AUTOSAR XML (schema 3.1.2)
package /Components/SWC_MPM
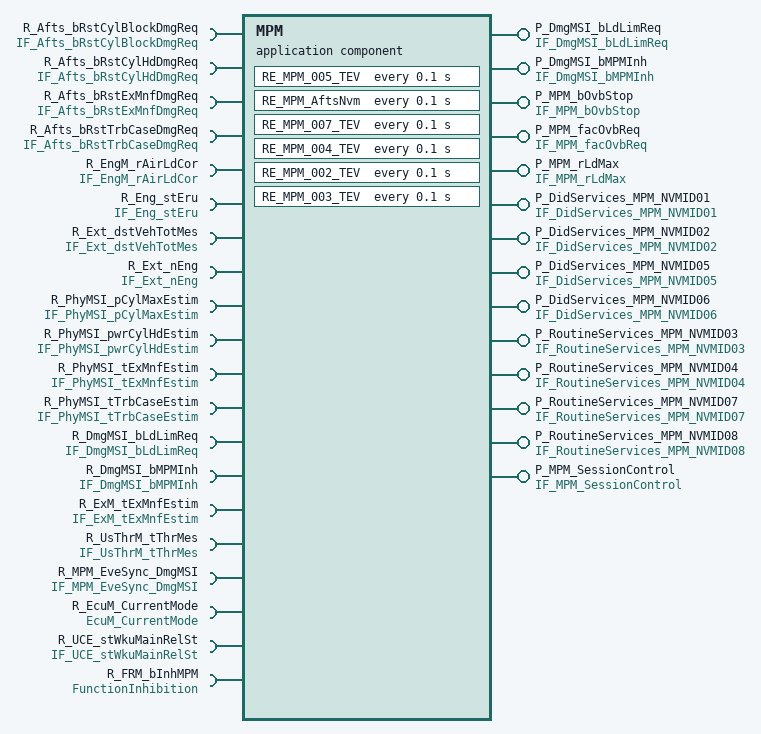
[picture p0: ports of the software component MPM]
  application software component type MPM
    20 x require port:
      R_Afts_bRstCylBlockDmgReq: unqueued-receiver-com-spec{data-element=Afts_bRstCylBlockDmgReq, init-value=ConstantValue, resync-time=0}, required-interface=IF_Afts_bRstCylBlockDmgReq  # Receiver of interface IF_Afts_bRstCylBlockDmgReq - Requirement Reference: [01552_11_02147-MPM-I003(0)]
      R_Afts_bRstCylHdDmgReq: unqueued-receiver-com-spec{data-element=Afts_bRstCylHdDmgReq, init-value=ConstantValue1, resync-time=0}, required-interface=IF_Afts_bRstCylHdDmgReq  # Receiver of interface IF_Afts_bRstCylHdDmgReq - Requirement Reference: [01552_11_02147-MPM-I004(0)]
      R_Afts_bRstExMnfDmgReq: unqueued-receiver-com-spec{data-element=Afts_bRstExMnfDmgReq, init-value=ConstantValue3, resync-time=0}, required-interface=IF_Afts_bRstExMnfDmgReq  # Receiver of interface IF_Afts_bRstExMnfDmgReq - Requirement Reference: [01552_11_02147-MPM-I005(0)]
      R_Afts_bRstTrbCaseDmgReq: unqueued-receiver-com-spec{data-element=Afts_bRstTrbCaseDmgReq, init-value=ConstantValue5, resync-time=0}, required-interface=IF_Afts_bRstTrbCaseDmgReq  # Receiver of interface IF_Afts_bRstTrbCaseDmgReq - Requirement Reference: [01552_11_02147-MPM-I006(0)]
      R_EngM_rAirLdCor: unqueued-receiver-com-spec{data-element=EngM_rAirLdCor, init-value=ConstantValue7, resync-time=0}, required-interface=IF_EngM_rAirLdCor  # Receiver of interface IF_EngM_rAirLdCor - Requirement Reference: [01552_11_02147-MPM-I007(0)]
      R_Eng_stEru: unqueued-receiver-com-spec{data-element=Eng_stEru, init-value=ConstantValue9, resync-time=0}, required-interface=IF_Eng_stEru  # Receiver of interface IF_Eng_stEru - Requirement Reference: [01552_11_02147-MPM-I008(0)]
      R_Ext_dstVehTotMes: unqueued-receiver-com-spec{data-element=Ext_dstVehTotMes, init-value=ConstantValue11, resync-time=0}, required-interface=IF_Ext_dstVehTotMes  # Receiver of interface IF_Ext_dstVehTotMes - Requirement Reference: [01552_11_02147-MPM-I009(0)]
      R_Ext_nEng: unqueued-receiver-com-spec{data-element=Ext_nEng, init-value=ConstantValue13, resync-time=0}, required-interface=IF_Ext_nEng  # Receiver of interface IF_Ext_nEng - Requirement Reference: [01552_11_02147-MPM-I010(0)]
      R_PhyMSI_pCylMaxEstim: unqueued-receiver-com-spec{data-element=PhyMSI_pCylMaxEstim, init-value=ConstantValue15, resync-time=0}, required-interface=IF_PhyMSI_pCylMaxEstim  # Receiver of interface IF_PhyMSI_pCylMaxEstim - Requirement Reference: [01552_11_02147-MPM-I011(0)]
      R_PhyMSI_pwrCylHdEstim: unqueued-receiver-com-spec{data-element=PhyMSI_pwrCylHdEstim, init-value=ConstantValue17, resync-time=0}, required-interface=IF_PhyMSI_pwrCylHdEstim  # Receiver of interface IF_PhyMSI_pwrCylHdEstim - Requirement Reference: [01552_11_02147-MPM-I012(0)]
      R_PhyMSI_tExMnfEstim: unqueued-receiver-com-spec{data-element=PhyMSI_tExMnfEstim, init-value=ConstantValue19, resync-time=0}, required-interface=IF_PhyMSI_tExMnfEstim  # Receiver of interface IF_PhyMSI_tExMnfEstim - Requirement Reference: [01552_11_02147-MPM-I013(0)]
      R_PhyMSI_tTrbCaseEstim: unqueued-receiver-com-spec{data-element=PhyMSI_tTrbCaseEstim, init-value=ConstantValue21, resync-time=0}, required-interface=IF_PhyMSI_tTrbCaseEstim  # Receiver of interface IF_PhyMSI_tTrbCaseEstim - Requirement Reference: [01552_11_02147-MPM-I014(0)]
      R_DmgMSI_bLdLimReq: unqueued-receiver-com-spec{data-element=DmgMSI_bLdLimReq, init-value=ConstantValue23, resync-time=0}, required-interface=IF_DmgMSI_bLdLimReq  # Receiver of interface IF_DmgMSI_bLdLimReq - Requirement Reference: [01552_11_02147-MPM-I018(0)]
      R_DmgMSI_bMPMInh: unqueued-receiver-com-spec{data-element=DmgMSI_bMPMInh, init-value=ConstantValue25, resync-time=0}, required-interface=IF_DmgMSI_bMPMInh  # Receiver of interface IF_DmgMSI_bMPMInh - Requirement Reference: [01552_11_02147-MPM-I019(0)]
      R_ExM_tExMnfEstim: unqueued-receiver-com-spec{data-element=ExM_tExMnfEstim, init-value=ConstantValue27, resync-time=0}, required-interface=IF_ExM_tExMnfEstim  # Receiver of interface IF_ExM_tExMnfEstim - Requirement Reference: [01552_11_02147-MPM-I020(0)]
      R_UsThrM_tThrMes: unqueued-receiver-com-spec{data-element=UsThrM_tThrMes, init-value=ConstantValue29, resync-time=0}, required-interface=IF_UsThrM_tThrMes  # Receiver of interface IF_UsThrM_tThrMes - Requirement Reference: [01552_11_02147-MPM-I021(0)]
      R_MPM_EveSync_DmgMSI: unqueued-receiver-com-spec{data-element=MPM_EveSync_DmgMSI, init-value=ConstantValue31, resync-time=0}, required-interface=IF_MPM_EveSync_DmgMSI  # Receiver of interface IF_MPM_EveSync_DmgMSI - Requirement Reference: [01552_11_02147-MPM-I022(0)]
      R_EcuM_CurrentMode: required-interface=EcuM_CurrentMode
      R_UCE_stWkuMainRelSt: required-interface=IF_UCE_stWkuMainRelSt
      R_FRM_bInhMPM: required-interface=FunctionInhibition  # 01552_11_02147-MPM-I095(0)
    14 x provide port:
      P_DmgMSI_bLdLimReq: unqueued-sender-com-spec{data-element=DmgMSI_bLdLimReq, can-invalidate=false, init-value=DmgMSI_bLdLimReq_Cst}, provided-interface=IF_DmgMSI_bLdLimReq
      P_DmgMSI_bMPMInh: unqueued-sender-com-spec{data-element=DmgMSI_bMPMInh, can-invalidate=false, init-value=DmgMSI_bMPMInh_Cst}, provided-interface=IF_DmgMSI_bMPMInh
      P_MPM_bOvbStop: unqueued-sender-com-spec{data-element=MPM_bOvbStop, can-invalidate=false, init-value=ConstantValue33}, provided-interface=IF_MPM_bOvbStop
      P_MPM_facOvbReq: unqueued-sender-com-spec{data-element=MPM_facOvbReq, can-invalidate=false, init-value=ConstantValue35}, provided-interface=IF_MPM_facOvbReq
      P_MPM_rLdMax: unqueued-sender-com-spec{data-element=MPM_rLdMax, can-invalidate=false, init-value=ConstantValue37}, provided-interface=IF_MPM_rLdMax
      P_DidServices_MPM_NVMID01: provided-interface=IF_DidServices_MPM_NVMID01
        provided-com-specs:
          operation=ConditionCheckWrite, queue-length=1
          operation=WriteData, queue-length=1
          operation=ConditionCheckRead, queue-length=1
          operation=ReadDataLength, queue-length=1
          operation=ReadData, queue-length=1
      P_DidServices_MPM_NVMID02: provided-interface=IF_DidServices_MPM_NVMID02
        provided-com-specs:
          operation=ReadData, queue-length=1
          operation=ConditionCheckRead, queue-length=1
          operation=ConditionCheckWrite, queue-length=1
          operation=WriteData, queue-length=1
          operation=ReadDataLength, queue-length=1
      P_DidServices_MPM_NVMID05: provided-interface=IF_DidServices_MPM_NVMID05
        provided-com-specs:
          operation=ConditionCheckRead, queue-length=1
          operation=ReadData, queue-length=1
          operation=ConditionCheckWrite, queue-length=1
          operation=WriteData, queue-length=1
          operation=ReadDataLength, queue-length=1
      P_DidServices_MPM_NVMID06: provided-interface=IF_DidServices_MPM_NVMID06
        provided-com-specs:
          operation=ConditionCheckRead, queue-length=1
          operation=ConditionCheckWrite, queue-length=1
          operation=ReadData, queue-length=1
          operation=ReadDataLength, queue-length=1
          operation=WriteData, queue-length=1
      P_RoutineServices_MPM_NVMID03: provided-com-specs=[{operation=Start, queue-length=1}, {operation=RequestResults, queue-length=1}], provided-interface=IF_RoutineServices_MPM_NVMID03
      P_RoutineServices_MPM_NVMID04: provided-com-specs=[{operation=Start, queue-length=1}, {operation=RequestResults, queue-length=1}], provided-interface=IF_RoutineServices_MPM_NVMID04
      P_RoutineServices_MPM_NVMID07: provided-com-specs=[{operation=RequestResults, queue-length=1}, {operation=Start, queue-length=1}], provided-interface=IF_RoutineServices_MPM_NVMID07
      P_RoutineServices_MPM_NVMID08: provided-com-specs=[{operation=RequestResults, queue-length=1}, {operation=Start, queue-length=1}], provided-interface=IF_RoutineServices_MPM_NVMID08
      P_MPM_SessionControl: provided-com-specs=[{operation=GetSesChgPermission, queue-length=1}, {operation=ChangeIndication, queue-length=1}], provided-interface=IF_MPM_SessionControl
  32 x constant specification:
    ConstantValue
      value:
        boolean literal ConstantValue: type=DT_Afts_bRstCylBlockDmgReq, value=false
    ConstantValue1
      value:
        boolean literal ConstantValue1: type=DT_Afts_bRstCylHdDmgReq, value=false
    ConstantValue11
      value:
        integer literal ConstantValue11: type=DT_Ext_dstVehTotMes, value=0
    ConstantValue13
      value:
        integer literal ConstantValue13: type=DT_Ext_nEng, value=0
    ConstantValue15
      value:
        integer literal ConstantValue15: type=DT_PhyMSI_pCylMaxEstim, value=0
    ConstantValue17
      value:
        integer literal ConstantValue17: type=DT_PhyMSI_pwrCylHdEstim, value=0
    ConstantValue19
      value:
        integer literal ConstantValue19: type=DT_PhyMSI_tExMnfEstim, value=7136
    ConstantValue21
      value:
        integer literal ConstantValue21: type=DT_PhyMSI_tTrbCaseEstim, value=7136
    ConstantValue23
      value:
        boolean literal ConstantValue23: type=DT_DmgMSI_bLdLimReq, value=false
    ConstantValue25
      value:
        boolean literal ConstantValue25: type=DT_DmgMSI_bMPMInh, value=false
    ConstantValue27
      value:
        integer literal ConstantValue27: type=DT_ExM_tExMnfEstim, value=4800
    ConstantValue29
      value:
        integer literal ConstantValue29: type=DT_UsThrM_tThrMes, value=0
    ConstantValue3
      value:
        boolean literal ConstantValue3: type=DT_Afts_bRstExMnfDmgReq, value=false
    ConstantValue31
      value:
        boolean literal ConstantValue31: type=DT_MPM_EveSync_DmgMSI, value=false
    ConstantValue33
      value:
        boolean literal ConstantValue33: type=DT_MPM_bOvbStop, value=false
    ConstantValue35
      value:
        integer literal ConstantValue35: type=DT_MPM_facOvbReq, value=0
    ConstantValue37
      value:
        integer literal ConstantValue37: type=DT_MPM_rLdMax, value=0
    ConstantValue5
      value:
        boolean literal ConstantValue5: type=DT_Afts_bRstTrbCaseDmgReq, value=false
    ConstantValue7
      value:
        integer literal ConstantValue7: type=DT_EngM_rAirLdCor, value=0
    ConstantValue9
      value:
        integer literal ConstantValue9: type=DT_Eng_stEru, value=1
    DmgMSI_bLdLimReq_Cst
      value:
        boolean literal DmgMSI_bLdLimReq_Cst: type=DT_DmgMSI_bLdLimReq, value=false
    DmgMSI_bMPMInh_Cst
      value:
        boolean literal DmgMSI_bMPMInh_Cst: type=DT_DmgMSI_bMPMInh, value=false
    DmgMSI_rCylBlockDmg_Cst
      value:
        integer literal DmgMSI_rCylBlockDmg_Cst: type=DT_DmgMSI_rCylBlockDmg, value=0
    DmgMSI_rCylHdDmg_Cst
      value:
        integer literal DmgMSI_rCylHdDmg_Cst: type=DT_DmgMSI_rCylHdDmg, value=0
    DmgMSI_rCylHdInjDmgCnt_Cst
      value:
        integer literal DmgMSI_rCylHdInjDmgCnt_Cst: type=DT_DmgMSI_rCylHdInjDmgCnt, value=0
    DmgMSI_rExMnfDmg_Cst
      value:
        integer literal DmgMSI_rExMnfDmg_Cst: type=DT_DmgMSI_rExMnfDmg, value=0
    DmgMSI_rTrbCaseDmg_Cst
      value:
        integer literal DmgMSI_rTrbCaseDmg_Cst: type=DT_DmgMSI_rTrbCaseDmg, value=0
    MPM_ctLockRqAftsNvm_Cst
      value:
        integer literal MPM_ctLockRqAftsNvm_Cst: type=DT_MPM_ctLockRqAftsNvm, value=0
    MPM_IDAftsNvm_Cst
      value:
        integer literal MPM_IDAftsNvm_Cst: type=DT_MPM_IDAftsNvm, value=0
    MPM_LockedAftsNvm_Cst
      value:
        boolean literal MPM_LockedAftsNvm_Cst: type=DT_MPM_LockedAftsNvm, value=false
    MPM_stAftsNvm_Cst
      value:
        integer literal MPM_stAftsNvm_Cst: type=DT_MPM_stAftsNvm, value=0
    MPM_stRstNvmRtn_Cst
      value:
        integer literal MPM_stRstNvmRtn_Cst: type=DT_MPM_stRstNvmRtn, value=0
  internal behavior IB_MPM: component=MPM
    operation invoked event EV_MPM_RstStart_NVMID07: start-on-event=RE_MPM_RstStart, operation=P_RoutineServices_MPM_NVMID07.Start
    operation invoked event EV_MPM_AftsGetSesChgPerm: start-on-event=RE_MPM_AftsGetSesChgPerm, operation=P_MPM_SessionControl.GetSesChgPermission
    operation invoked event EV_MPM_AftsNvmChkRead_NVMID02: start-on-event=RE_MPM_AftsNvmChkRead, operation=P_DidServices_MPM_NVMID02.ConditionCheckRead
    mode switch event EV_MPM_AftrsInit: start-on-event=RE_MPM_AftrsInit, activation=ENTRY, mode=R_EcuM_CurrentMode.currentMode.RUN
    operation invoked event EV_MPM_AftsNvmRead_NVMID01: start-on-event=RE_MPM_AftsNvmRead, operation=P_DidServices_MPM_NVMID01.ReadData
    operation invoked event EV_MPM_RstStart_NVMID08: start-on-event=RE_MPM_RstStart, operation=P_RoutineServices_MPM_NVMID08.Start
    data received event EV_MPM_006_DRE: start-on-event=RE_MPM_006_DRE, data=R_MPM_EveSync_DmgMSI.MPM_EveSync_DmgMSI
    timing event EV_MPM_005_TEV: mode-dependency=dependent-on-mode=[R_UCE_stWkuMainRelSt.RCD_stWkuMainRelSt.Invalid, R_UCE_stWkuMainRelSt.RCD_stWkuMainRelSt.PostMainWakeUp, R_UCE_stWkuMainRelSt.RCD_stWkuMainRelSt.PreMainWakeUp], start-on-event=RE_MPM_005_TEV, period=0.1
    4 x operation invoked event:
      EV_MPM_AftsNvmRDL_NVMID06: start-on-event=RE_MPM_AftsNvmRDL, operation=P_DidServices_MPM_NVMID06.ReadDataLength
      EV_MPM_AftsNvmRDL_NVMID05: start-on-event=RE_MPM_AftsNvmRDL, operation=P_DidServices_MPM_NVMID05.ReadDataLength
      EV_MPM_RstRqResults_NVMID04: start-on-event=RE_MPM_RstRqResults, operation=P_RoutineServices_MPM_NVMID04.RequestResults
      EV_MPM_AftsNvmWrite_NVMID01: start-on-event=RE_MPM_AftsNvmWrite, operation=P_DidServices_MPM_NVMID01.WriteData
    timing event EV_MPM_AftsNvm: mode-dependency=dependent-on-mode=[R_UCE_stWkuMainRelSt.RCD_stWkuMainRelSt.Invalid, R_UCE_stWkuMainRelSt.RCD_stWkuMainRelSt.PostMainWakeUp, R_UCE_stWkuMainRelSt.RCD_stWkuMainRelSt.PreMainWakeUp], start-on-event=RE_MPM_AftsNvm, period=0.1
    operation invoked event EV_MPM_AftsNvmWrite_NVMID06: start-on-event=RE_MPM_AftsNvmWrite, operation=P_DidServices_MPM_NVMID06.WriteData
    timing event EV_MPM_007_TEV: mode-dependency=dependent-on-mode=[R_UCE_stWkuMainRelSt.RCD_stWkuMainRelSt.Invalid, R_UCE_stWkuMainRelSt.RCD_stWkuMainRelSt.PostMainWakeUp, R_UCE_stWkuMainRelSt.RCD_stWkuMainRelSt.PreMainWakeUp], start-on-event=RE_MPM_007_TEV, period=0.1
    11 x operation invoked event:
      EV_MPM_AftsNvmChkWrite_NVMID02: start-on-event=RE_MPM_AftsNvmChkWrite, operation=P_DidServices_MPM_NVMID02.ConditionCheckWrite
      EV_MPM_AftsNvmChkWrite_NVMID05: start-on-event=RE_MPM_AftsNvmChkWrite, operation=P_DidServices_MPM_NVMID05.ConditionCheckWrite
      EV_MPM_RstRqResults_NVMID03: start-on-event=RE_MPM_RstRqResults, operation=P_RoutineServices_MPM_NVMID03.RequestResults
      EV_MPM_AftsNvmChkWrite_NVMID01: start-on-event=RE_MPM_AftsNvmChkWrite, operation=P_DidServices_MPM_NVMID01.ConditionCheckWrite
      EV_MPM_AftsNvmRead_NVMID06: start-on-event=RE_MPM_AftsNvmRead, operation=P_DidServices_MPM_NVMID06.ReadData
      EV_MPM_RstStart_NVMID03: start-on-event=RE_MPM_RstStart, operation=P_RoutineServices_MPM_NVMID03.Start
      EV_MPM_AftsNvmRDL_NVMID02: start-on-event=RE_MPM_AftsNvmRDL, operation=P_DidServices_MPM_NVMID02.ReadDataLength
      EV_MPM_AftsNvmRead_NVMID05: start-on-event=RE_MPM_AftsNvmRead, operation=P_DidServices_MPM_NVMID05.ReadData
      EV_MPM_AftsNvmChkRead_NVMID06: start-on-event=RE_MPM_AftsNvmChkRead, operation=P_DidServices_MPM_NVMID06.ConditionCheckRead
      EV_MPM_RstRqResults_NVMID08: start-on-event=RE_MPM_RstRqResults, operation=P_RoutineServices_MPM_NVMID08.RequestResults
      EV_MPM_RstStart_NVMID04: start-on-event=RE_MPM_RstStart, operation=P_RoutineServices_MPM_NVMID04.Start
    mode switch event EV_MPM_001_MSE: start-on-event=RE_MPM_001_MSE, activation=ENTRY, mode=R_EcuM_CurrentMode.currentMode.RUN
    operation invoked event EV_MPM_AftsNvmWrite_NVMID02: start-on-event=RE_MPM_AftsNvmWrite, operation=P_DidServices_MPM_NVMID02.WriteData
    timing event EV_MPM_004_TEV: mode-dependency=dependent-on-mode=[R_UCE_stWkuMainRelSt.RCD_stWkuMainRelSt.Invalid, R_UCE_stWkuMainRelSt.RCD_stWkuMainRelSt.PostMainWakeUp, R_UCE_stWkuMainRelSt.RCD_stWkuMainRelSt.PreMainWakeUp], start-on-event=RE_MPM_004_TEV, period=0.1
    timing event EV_MPM_002_TEV: mode-dependency=dependent-on-mode=[R_UCE_stWkuMainRelSt.RCD_stWkuMainRelSt.Invalid, R_UCE_stWkuMainRelSt.RCD_stWkuMainRelSt.PostMainWakeUp, R_UCE_stWkuMainRelSt.RCD_stWkuMainRelSt.PreMainWakeUp], start-on-event=RE_MPM_002_TEV, period=0.1
    4 x operation invoked event:
      EV_MPM_AftsNvmChkRead_NVMID05: start-on-event=RE_MPM_AftsNvmChkRead, operation=P_DidServices_MPM_NVMID05.ConditionCheckRead
      EV_MPM_AftsNvmChkWrite_NVMID06: start-on-event=RE_MPM_AftsNvmChkWrite, operation=P_DidServices_MPM_NVMID06.ConditionCheckWrite
      EV_MPM_AftsNvmRDL_NVMID01: start-on-event=RE_MPM_AftsNvmRDL, operation=P_DidServices_MPM_NVMID01.ReadDataLength
      EV_MPM_AftsSesChgInd: start-on-event=RE_MPM_AftsSesChgInd, operation=P_MPM_SessionControl.ChangeIndication
    timing event EV_MPM_003_TEV: mode-dependency=dependent-on-mode=[R_UCE_stWkuMainRelSt.RCD_stWkuMainRelSt.Invalid, R_UCE_stWkuMainRelSt.RCD_stWkuMainRelSt.PostMainWakeUp, R_UCE_stWkuMainRelSt.RCD_stWkuMainRelSt.PreMainWakeUp], start-on-event=RE_MPM_003_TEV, period=0.1
    4 x operation invoked event:
      EV_MPM_RstRqResults_NVMID07: start-on-event=RE_MPM_RstRqResults, operation=P_RoutineServices_MPM_NVMID07.RequestResults
      EV_MPM_AftsNvmChkRead_NVMID01: start-on-event=RE_MPM_AftsNvmChkRead, operation=P_DidServices_MPM_NVMID01.ConditionCheckRead
      EV_MPM_AftsNvmRead_NVMID02: start-on-event=RE_MPM_AftsNvmRead, operation=P_DidServices_MPM_NVMID02.ReadData
      EV_MPM_AftsNvmWrite_NVMID05: start-on-event=RE_MPM_AftsNvmWrite, operation=P_DidServices_MPM_NVMID05.WriteData
    10 x inter runnable variable, all with sw-calibration-access=READ-WRITE, communication-approach=EXPLICIT:
      DmgMSI_rExMnfDmg: type=DT_DmgMSI_rExMnfDmg, init-value=DmgMSI_rExMnfDmg_Cst  # [01552_11_02147-MPM-I050(0)] - Endommage du collecteur échappement estimé
      DmgMSI_rCylHdDmg: type=DT_DmgMSI_rCylHdDmg, init-value=DmgMSI_rCylHdDmg_Cst  # [01552_11_02147-MPM-I072(0)] - Endommage estimé du pontet culasse
      DmgMSI_rCylHdInjDmgCnt: type=DT_DmgMSI_rCylHdInjDmgCnt, init-value=DmgMSI_rCylHdInjDmgCnt_Cst  # [01552_11_02147-MPM-I025(0)] - Endommage principal du noyau d'eau culasse estimé
      MPM_ctLockRqAftsNvm: type=DT_MPM_ctLockRqAftsNvm, init-value=MPM_ctLockRqAftsNvm_Cst  # [01552_11_02147-MPM-I108(0)] - guarantee the consistency of the data and support RDBI request to read several DIDs
      MPM_stRstNvmRtn: type=DT_MPM_stRstNvmRtn, init-value=MPM_stRstNvmRtn_Cst  # [01552_11_02147-MPM-I111(0)] - status of the corresponding routine service
      DmgMSI_rCylBlockDmg: type=DT_DmgMSI_rCylBlockDmg, init-value=DmgMSI_rCylBlockDmg_Cst  # [01552_11_02147-MPM-I026(2)] - Endommage du fond de filet estimé
      MPM_IDAftsNvm: type=DT_MPM_IDAftsNvm, init-value=MPM_IDAftsNvm_Cst  # [01552_11_02147-MPM-I110(0)] - manage which NVMID to handle
      MPM_stAftsNvm: type=DT_MPM_stAftsNvm, init-value=MPM_stAftsNvm_Cst  # [01552_11_02147-MPM-I107(0)] - Manage the type of aftersale service called
      DmgMSI_rTrbCaseDmg: type=DT_DmgMSI_rTrbCaseDmg, init-value=DmgMSI_rTrbCaseDmg_Cst  # [01552_11_02147-MPM-I028(0)] - Endommage du carter turbine estimé
      MPM_LockedAftsNvm: type=DT_MPM_LockedAftsNvm, init-value=MPM_LockedAftsNvm_Cst  # [01552_11_02147-MPM-I109(0)] - the consistency of the data is guarantee
    port-api-option enable-take-address=false, indirect-api=false, port=P_RoutineServices_MPM_NVMID08:
      port-arg-values:
        integer literal PAV_MPM_NVMID08: type=UInt8, value=8
    port-api-option enable-take-address=false, indirect-api=false, port=P_DidServices_MPM_NVMID01:
      port-arg-values:
        integer literal PAV_MPM_NVMID01: type=UInt8, value=1
    port-api-option enable-take-address=false, indirect-api=false, port=P_RoutineServices_MPM_NVMID07:
      port-arg-values:
        integer literal PAV_MPM_NVMID07: type=UInt8, value=7
    port-api-option enable-take-address=false, indirect-api=false, port=P_DidServices_MPM_NVMID05:
      port-arg-values:
        integer literal PAV_MPM_NVMID05: type=UInt8, value=5
    port-api-option enable-take-address=false, indirect-api=false, port=P_RoutineServices_MPM_NVMID03:
      port-arg-values:
        integer literal PAV_MPM_NVMID03: type=UInt8, value=3
    port-api-option enable-take-address=false, indirect-api=false, port=P_DidServices_MPM_NVMID06:
      port-arg-values:
        integer literal PAV_MPM_NVMID06: type=UInt8, value=6
    port-api-option enable-take-address=false, indirect-api=false, port=P_RoutineServices_MPM_NVMID04:
      port-arg-values:
        integer literal PAV_MPM_NVMID04: type=UInt8, value=4
    port-api-option enable-take-address=false, indirect-api=false, port=P_DidServices_MPM_NVMID02:
      port-arg-values:
        integer literal PAV_MPM_NVMID02: type=UInt8, value=2
    18 x runnable:
      RE_MPM_005_TEV: written-variable=DmgMSI_rCylHdDmg  # 01552_11_02147-MPM-A005(1)
        data receive point dr_Afts_bRstCylHdDmgReq: data-element=R_Afts_bRstCylHdDmgReq.Afts_bRstCylHdDmgReq
        data receive point dr_PhyMSI_pwrCylHdEstim: data-element=R_PhyMSI_pwrCylHdEstim.PhyMSI_pwrCylHdEstim
        data receive point dr_Eng_stEru: data-element=R_Eng_stEru.Eng_stEru
      RE_MPM_AftsNvm: read-variable=[MPM_stAftsNvm, MPM_IDAftsNvm, MPM_ctLockRqAftsNvm, MPM_LockedAftsNvm], written-variable=[MPM_stAftsNvm, MPM_ctLockRqAftsNvm, MPM_LockedAftsNvm]  # 01552_11_02147-MPM-A017(0)
        data receive point dr_Ext_nEng: data-element=R_Ext_nEng.Ext_nEng
      RE_MPM_RstStart: read-variable=[MPM_stAftsNvm, MPM_stRstNvmRtn, MPM_ctLockRqAftsNvm, MPM_IDAftsNvm], written-variable=[MPM_stAftsNvm, MPM_ctLockRqAftsNvm, MPM_IDAftsNvm]  # 01552_11_02147-MPM-A013(1)
        data receive point dr_Ext_nEng: data-element=R_Ext_nEng.Ext_nEng
      RE_MPM_AftsNvmChkRead: read-variable=[MPM_IDAftsNvm, MPM_stRstNvmRtn, MPM_stAftsNvm, MPM_ctLockRqAftsNvm, MPM_LockedAftsNvm], written-variable=[MPM_IDAftsNvm, MPM_stAftsNvm, MPM_ctLockRqAftsNvm, MPM_LockedAftsNvm]  # 01552_11_02147-MPM-A008(1)
        data receive point dr_Ext_nEng: data-element=R_Ext_nEng.Ext_nEng
      RE_MPM_RstRqResults: read-variable=[MPM_IDAftsNvm, MPM_stRstNvmRtn, MPM_stAftsNvm], written-variable=MPM_stAftsNvm  # 01552_11_02147-MPM-A014(1)
      RE_MPM_AftsNvmWrite: read-variable=MPM_stAftsNvm, written-variable=MPM_stAftsNvm  # 01552_11_02147-MPM-A011(1)
      RE_MPM_007_TEV  # 01552_11_02147-MPM-A007(0)
        5 x data receive point:
          dr_DmgMSI_bLdLimReq: data-element=R_DmgMSI_bLdLimReq.DmgMSI_bLdLimReq
          dr_UsThrM_tThrMes: data-element=R_UsThrM_tThrMes.UsThrM_tThrMes
          dr_Ext_nEng: data-element=R_Ext_nEng.Ext_nEng
          dr_DmgMSI_bMPMInh: data-element=R_DmgMSI_bMPMInh.DmgMSI_bMPMInh
          dr_ExM_tExMnfEstim: data-element=R_ExM_tExMnfEstim.ExM_tExMnfEstim
        data send point ds_MPM_facOvbReq: data-element=P_MPM_facOvbReq.MPM_facOvbReq
        data send point ds_MPM_bOvbStop: data-element=P_MPM_bOvbStop.MPM_bOvbStop
        data send point ds_MPM_rLdMax: data-element=P_MPM_rLdMax.MPM_rLdMax
        sync call SC_FRM_bInhMPM: operation=R_FRM_bInhMPM.GetFunctionPermission
      RE_MPM_004_TEV: written-variable=DmgMSI_rExMnfDmg  # 01552_11_02147-MPM-A004(1)
        data receive point dr_PhyMSI_tExMnfEstim: data-element=R_PhyMSI_tExMnfEstim.PhyMSI_tExMnfEstim
        data receive point dr_Eng_stEru: data-element=R_Eng_stEru.Eng_stEru
        data receive point dr_Afts_bRstExMnfDmgReq: data-element=R_Afts_bRstExMnfDmgReq.Afts_bRstExMnfDmgReq
      RE_MPM_AftsNvmRDL  # 01552_11_02147-MPM-A012(1)
      RE_MPM_003_TEV: written-variable=DmgMSI_rTrbCaseDmg  # 01552_11_02147-MPM-A003(1)
        data receive point dr_Eng_stEru: data-element=R_Eng_stEru.Eng_stEru
        data receive point dr_PhyMSI_tTrbCaseEstim: data-element=R_PhyMSI_tTrbCaseEstim.PhyMSI_tTrbCaseEstim
        data receive point dr_Afts_bRstTrbCaseDmgReq: data-element=R_Afts_bRstTrbCaseDmgReq.Afts_bRstTrbCaseDmgReq
      RE_MPM_AftsNvmRead: read-variable=[MPM_ctLockRqAftsNvm, MPM_LockedAftsNvm, MPM_stAftsNvm], written-variable=[MPM_ctLockRqAftsNvm, MPM_LockedAftsNvm, MPM_stAftsNvm]  # 01552_11_02147-MPM-A009(1)
      RE_MPM_002_TEV: read-variable=[DmgMSI_rCylBlockDmg, DmgMSI_rExMnfDmg, DmgMSI_rCylHdInjDmgCnt, DmgMSI_rTrbCaseDmg, DmgMSI_rCylHdDmg]  # 01552_11_02147-MPM-A002(0)
        data receive point dr_Ext_dstVehTotMes: data-element=R_Ext_dstVehTotMes.Ext_dstVehTotMes
        data send point ds_DmgMSI_bMPMInh: data-element=P_DmgMSI_bMPMInh.DmgMSI_bMPMInh
        data send point ds_DmgMSI_bLdLimReq: data-element=P_DmgMSI_bLdLimReq.DmgMSI_bLdLimReq
      RE_MPM_AftrsInit: written-variable=[MPM_LockedAftsNvm, MPM_ctLockRqAftsNvm, MPM_stAftsNvm, MPM_stRstNvmRtn, MPM_IDAftsNvm]  # 01552_11_02147-MPM-A018(0)
      RE_MPM_AftsNvmChkWrite: read-variable=[MPM_IDAftsNvm, MPM_LockedAftsNvm, MPM_stRstNvmRtn, MPM_ctLockRqAftsNvm, MPM_stAftsNvm], written-variable=[MPM_IDAftsNvm, MPM_LockedAftsNvm, MPM_ctLockRqAftsNvm, MPM_stAftsNvm]  # 01552_11_02147-MPM-A010(1)
        data receive point dr_Ext_nEng: data-element=R_Ext_nEng.Ext_nEng
      RE_MPM_006_DRE: written-variable=[DmgMSI_rCylBlockDmg, DmgMSI_rCylHdInjDmgCnt]  # 01552_11_02147-MPM-A006(1)
        6 x data receive point:
          dr_Afts_bRstCylHdDmgReq: data-element=R_Afts_bRstCylHdDmgReq.Afts_bRstCylHdDmgReq
          dr_PhyMSI_pwrCylHdEstim: data-element=R_PhyMSI_pwrCylHdEstim.PhyMSI_pwrCylHdEstim
          dr_Afts_bRstCylBlockDmgReq: data-element=R_Afts_bRstCylBlockDmgReq.Afts_bRstCylBlockDmgReq
          dr_PhyMSI_pCylMaxEstim: data-element=R_PhyMSI_pCylMaxEstim.PhyMSI_pCylMaxEstim
          dr_EngM_rAirLdCor: data-element=R_EngM_rAirLdCor.EngM_rAirLdCor
          dr_Ext_nEng: data-element=R_Ext_nEng.Ext_nEng
      RE_MPM_AftsSesChgInd: read-variable=MPM_stRstNvmRtn, written-variable=MPM_IDAftsNvm  # 01552_11_02147-MPM-A016(0)
      RE_MPM_001_MSE: written-variable=[DmgMSI_rCylHdDmg, DmgMSI_rCylBlockDmg, DmgMSI_rTrbCaseDmg, DmgMSI_rExMnfDmg, DmgMSI_rCylHdInjDmgCnt]  # 01552_11_02147-MPM-A001(0)
        5 x data send point:
          ds_MPM_bOvbStop: data-element=P_MPM_bOvbStop.MPM_bOvbStop
          ds_MPM_rLdMax: data-element=P_MPM_rLdMax.MPM_rLdMax
          ds_DmgMSI_bMPMInh: data-element=P_DmgMSI_bMPMInh.DmgMSI_bMPMInh
          ds_MPM_facOvbReq: data-element=P_MPM_facOvbReq.MPM_facOvbReq
          ds_DmgMSI_bLdLimReq: data-element=P_DmgMSI_bLdLimReq.DmgMSI_bLdLimReq
      RE_MPM_AftsGetSesChgPerm  # 01552_11_02147-MPM-A015(0)
  swc implementation Imp_MPM: programming-language=C, behavior=IB_MPM
    code-descriptors:
      code CodeDescriptor: type=SRC
        13 x xfile:
          MPM_nvm_c: url=MPM_nvm.c
          MPM_Library_h: url=MPM_Library.h
          MPM_code_c: url=MPM_code.c
          MPM_c: url=MPM.c
          MPM_MemMap_h: url=MPM_MemMap.h
          MPM_Library_c: url=MPM_Library.c
          MPM_nvm_h: url=MPM_nvm.h
          MPM_h: url=MPM.h
          MPM_code_h: url=MPM_code.h
          MPM_calibrations_c: url=MPM_calibrations.c
          MPM_Aftrs_c: url=MPM_Aftrs.c
          MPM_calibrations_h: url=MPM_calibrations.h
          MPM_Aftrs_h: url=MPM_Aftrs.h
package /Components/SWC_MPM/MPM_IRVDatatypes
  boolean type DT_MPM_LockedAftsNvm: base-type=boolean
  9 x integer type, all with lower-limit=0:
    DT_DmgMSI_rCylBlockDmg: base-type=uint32, upper-limit=4294967295
    DT_DmgMSI_rCylHdDmg: base-type=uint32, upper-limit=4294967295
    DT_DmgMSI_rCylHdInjDmgCnt: base-type=uint16, upper-limit=65535
    DT_DmgMSI_rExMnfDmg: base-type=uint32, upper-limit=4294967295
    DT_DmgMSI_rTrbCaseDmg: base-type=uint32, upper-limit=4294967295
    DT_MPM_ctLockRqAftsNvm: base-type=uint8, upper-limit=255
    DT_MPM_IDAftsNvm: base-type=uint8, upper-limit=255
    DT_MPM_stAftsNvm: base-type=uint8, upper-limit=255
    DT_MPM_stRstNvmRtn: base-type=uint32, upper-limit=4294967295
